AUTOSAR XML (schema 4-2-2)
package /ComponentTypes
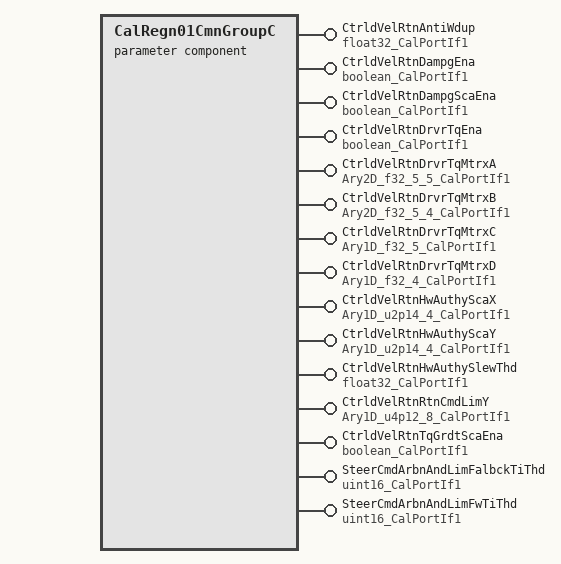
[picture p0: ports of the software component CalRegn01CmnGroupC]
  parameter sw component type CalRegn01CmnGroupC
    15 x provide port:
      CtrldVelRtnAntiWdup: parameter-provide-com-spec{init-value=1, parameter=Val}, provided-interface=float32_CalPortIf1
      CtrldVelRtnDampgEna: parameter-provide-com-spec{init-value=0, parameter=Logl}, provided-interface=boolean_CalPortIf1
      CtrldVelRtnDampgScaEna: parameter-provide-com-spec{init-value=0, parameter=Logl}, provided-interface=boolean_CalPortIf1
      CtrldVelRtnDrvrTqEna: parameter-provide-com-spec{init-value=0, parameter=Logl}, provided-interface=boolean_CalPortIf1
      CtrldVelRtnDrvrTqMtrxA: parameter-provide-com-spec{init-value=[[-0.17159, 0.00010352, 1.1696, 0.00024516, 1.9834e-05], [-240.58, 0.060289, 240.53, 0.17028, 0.047148], [0.0018246, -4.2826e-06, 0.99616, 0.00025897, -2.8965e-07], [-6.1943, 0.014635, 5.9127, 0.11656, 0.00098854], [-70.875, -0.28572, 70.86, 0.053221, 0.98679]], parameter=Ary2D}, provided-interface=Ary2D_f32_5_5_CalPortIf1
      CtrldVelRtnDrvrTqMtrxB: parameter-provide-com-spec{init-value=[[3.2994e-07, 0.0081464, 0.0019034, 0.0016485], [0.00045434, 1.6329, 0.0015119, 0.76734], [1.1488e-06, -2.4566e-05, 0.0019002, 0.001743], [0.0027499, 0.045004, 0.00025007, 0.86756], [0.0001448, 0.50816, -2.5948e-05, 0.23299]], parameter=Ary2D}, provided-interface=Ary2D_f32_5_4_CalPortIf1
      CtrldVelRtnDrvrTqMtrxC: parameter-provide-com-spec{init-value=[0, 0, 0, 0, 1], parameter=Ary1D}, provided-interface=Ary1D_f32_5_CalPortIf1
      CtrldVelRtnDrvrTqMtrxD: parameter-provide-com-spec{init-value=[0, 0, 0, 0], parameter=Ary1D}, provided-interface=Ary1D_f32_4_CalPortIf1
      CtrldVelRtnHwAuthyScaX: parameter-provide-com-spec{init-value=[0, 8192, 12288, 16384], parameter=Ary1D}, provided-interface=Ary1D_u2p14_4_CalPortIf1
      CtrldVelRtnHwAuthyScaY: parameter-provide-com-spec{init-value=[0, 0, 0, 16384], parameter=Ary1D}, provided-interface=Ary1D_u2p14_4_CalPortIf1
      CtrldVelRtnHwAuthySlewThd: parameter-provide-com-spec{init-value=0.5, parameter=Val}, provided-interface=float32_CalPortIf1
      CtrldVelRtnRtnCmdLimY: parameter-provide-com-spec{init-value=8 x 16384, parameter=Ary1D}, provided-interface=Ary1D_u4p12_8_CalPortIf1
      CtrldVelRtnTqGrdtScaEna: parameter-provide-com-spec{init-value=0, parameter=Logl}, provided-interface=boolean_CalPortIf1
      SteerCmdArbnAndLimFalbckTiThd: parameter-provide-com-spec{init-value=1000, parameter=Val}, provided-interface=uint16_CalPortIf1
      SteerCmdArbnAndLimFwTiThd: parameter-provide-com-spec{init-value=100, parameter=Val}, provided-interface=uint16_CalPortIf1
